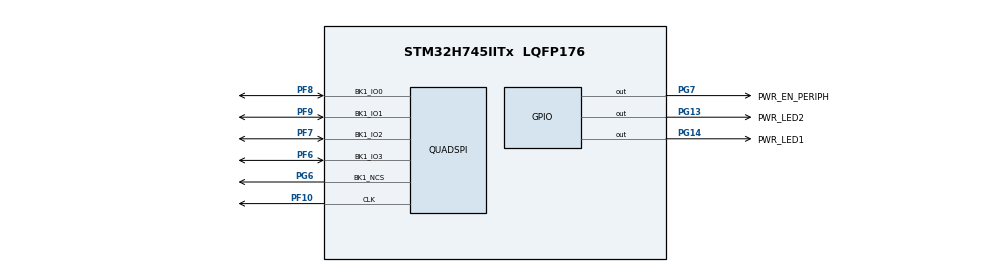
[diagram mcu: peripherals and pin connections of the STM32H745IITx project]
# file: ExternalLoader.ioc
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CortexM4.IPs=BDMA,CORTEX_M4\:I,DEBUG,DMA,FATFS_M4\:I,FREERTOS_M4\:I,IWDG2\:I,MDMA,NVIC2\:I,OPENAMP_M4\:I,PDM2PCM_M4\:I,PWR,RCC,RESMGR_UTILITY,SYS_M4\:I,USB_DEVICE_M4\:I,USB_HOST_M4\:I,VREFBUF,WWDG2\:I
CortexM7.IPs=BDMA\:I,CORTEX_M7\:I,DEBUG\:I,DMA\:I,FATFS_M7\:I,FREERTOS_M7\:I,IWDG1\:I,MDMA\:I,NVIC1\:I,OPENAMP_M7\:I,PDM2PCM_M7\:I,PWR\:I,RCC\:I,RESMGR_UTILITY\:I,SYS\:I,USB_DEVICE_M7\:I,USB_HOST_M7\:I,VREFBUF\:I,WWDG1\:I,QUADSPI\:I
CortexM7.Pins=PG7,PG13,PG14
Mcu.Family=STM32H7
Mcu.Name=STM32H745IITx
Mcu.Package=LQFP176
NVIC1.PriorityGroup=NVIC_PRIORITYGROUP_4
NVIC2.PriorityGroup=NVIC_PRIORITYGROUP_4
PA13\ (JTMS/SWDIO).Mode=Serial_Wire
PA13\ (JTMS/SWDIO).PinAttribute=CortexM7
PA13\ (JTMS/SWDIO).Signal=DEBUG_JTMS-SWDIO
PA14\ (JTCK/SWCLK).Mode=Serial_Wire
PA14\ (JTCK/SWCLK).PinAttribute=CortexM7
PA14\ (JTCK/SWCLK).Signal=DEBUG_JTCK-SWCLK
PF10.GPIO_Speed=GPIO_SPEED_FREQ_VERY_HIGH
PF10.Mode=Single Bank 1
PF10.PinAttribute=CortexM7
PF10.Signal=QUADSPI_CLK
PF6.GPIO_Speed=GPIO_SPEED_FREQ_VERY_HIGH
PF6.Mode=Single Bank 1
PF6.PinAttribute=CortexM7
PF6.Signal=QUADSPI_BK1_IO3
PF7.GPIO_Speed=GPIO_SPEED_FREQ_VERY_HIGH
PF7.Mode=Single Bank 1
PF7.PinAttribute=CortexM7
PF7.Signal=QUADSPI_BK1_IO2
PF8.GPIO_Speed=GPIO_SPEED_FREQ_VERY_HIGH
PF8.Mode=Single Bank 1
PF8.PinAttribute=CortexM7
PF8.Signal=QUADSPI_BK1_IO0
PF9.GPIO_Speed=GPIO_SPEED_FREQ_VERY_HIGH
PF9.Mode=Single Bank 1
PF9.PinAttribute=CortexM7
PF9.Signal=QUADSPI_BK1_IO1
PG13.GPIO_Label=PWR_LED2
PG13.PinAttribute=CortexM7
PG13.Signal=GPIO_Output
PG14.GPIO_Label=PWR_LED1
PG14.PinAttribute=CortexM7
PG14.Signal=GPIO_Output
PG6.GPIO_Speed=GPIO_SPEED_FREQ_VERY_HIGH
PG6.Mode=Single Bank 1
PG6.PinAttribute=CortexM7
PG6.Signal=QUADSPI_BK1_NCS
PG7.GPIO_Label=PWR_EN_PERIPH
PG7.PinAttribute=CortexM7
PG7.Signal=GPIO_Output
ProjectManager.HeapSize=0x200
ProjectManager.StackSize=0x400
ProjectManager.TargetToolchain=STM32CubeIDE
QUADSPI.ChipSelectHighTime=QSPI_CS_HIGH_TIME_3_CYCLE
QUADSPI.ClockPrescaler=5
QUADSPI.FlashSize=25
RCC.ADCFreq_Value=129000000
RCC.APB1Freq_Value=64000000
RCC.APB2Freq_Value=64000000
RCC.APB3Freq_Value=64000000
RCC.APB4Freq_Value=64000000
RCC.CortexFreq_Value=64000000
RCC.HCLKFreq_Value=64000000
RCC.SYSCLKFreq_VALUE=64000000
RCC.USBFreq_Value=129000000
SYS.userName=SYS_M7
VP_SYS_M4_VS_Systick.Mode=SysTick
board=custom

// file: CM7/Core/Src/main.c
/* USER CODE BEGIN Header */
/**
  ******************************************************************************
  * @file           : main.c
  * @brief          : Main program body
  ******************************************************************************
  * @attention
  *
  * <h2><center>&copy; Copyright (c) 2020 STMicroelectronics.
  * All rights reserved.</center></h2>
  *
  * This software component is licensed by ST under BSD 3-Clause license,
  * the "License"; You may not use this file except in compliance with the
  * License. You may obtain a copy of the License at:
  *                        opensource.org/licenses/BSD-3-Clause
  *
  ******************************************************************************
  */
/* USER CODE END Header */
#include "main.h"
#include "quadspi.h"
#include "gpio.h"

/* USER CODE BEGIN PD */

#ifndef HSEM_ID_0
#define HSEM_ID_0 (0U) /* HW semaphore 0*/
#endif
/* USER CODE END PD */

void SystemClock_Config(void);

int main(void)
{
/* USER CODE BEGIN Boot_Mode_Sequence_0 */
  int32_t timeout;
/* USER CODE END Boot_Mode_Sequence_0 */

/* USER CODE BEGIN Boot_Mode_Sequence_1 */
  /* Wait until CPU2 boots and enters in stop mode or timeout*/
  timeout = 0xFFFF;
  while((__HAL_RCC_GET_FLAG(RCC_FLAG_D2CKRDY) != RESET) && (timeout-- > 0));
  if ( timeout < 0 )
  {
  Error_Handler();
  }
/* USER CODE END Boot_Mode_Sequence_1 */
  /* MCU Configuration--------------------------------------------------------*/

  /* Reset of all peripherals, Initializes the Flash interface and the Systick. */
  HAL_Init();

  /* Configure the system clock */
  SystemClock_Config();
/* USER CODE BEGIN Boot_Mode_Sequence_2 */
/* When system initialization is finished, Cortex-M7 will release Cortex-M4 by means of
HSEM notification */
/*HW semaphore Clock enable*/
__HAL_RCC_HSEM_CLK_ENABLE();
/*Take HSEM */
HAL_HSEM_FastTake(HSEM_ID_0);
/*Release HSEM in order to notify the CPU2(CM4)*/
HAL_HSEM_Release(HSEM_ID_0,0);
/* wait until CPU2 wakes up from stop mode */
timeout = 0xFFFF;
while((__HAL_RCC_GET_FLAG(RCC_FLAG_D2CKRDY) == RESET) && (timeout-- > 0));
if ( timeout < 0 )
{
Error_Handler();
}
/* USER CODE END Boot_Mode_Sequence_2 */

  /* Initialize all configured peripherals */
  MX_GPIO_Init();
  MX_QUADSPI_Init();
  /* USER CODE BEGIN 2 */
  if (CSP_QUADSPI_Init() == HAL_OK)
  {

  }
  /* USER CODE END 2 */

  /* Infinite loop */
  while (1)
  {

  }
}

void SystemClock_Config(void)
{
  RCC_OscInitTypeDef RCC_OscInitStruct = {0};
  RCC_ClkInitTypeDef RCC_ClkInitStruct = {0};
  RCC_PeriphCLKInitTypeDef PeriphClkInitStruct = {0};

  /** Supply configuration update enable
  */
  HAL_PWREx_ConfigSupply(PWR_DIRECT_SMPS_SUPPLY);
  /** Configure the main internal regulator output voltage
  */
  __HAL_PWR_VOLTAGESCALING_CONFIG(PWR_REGULATOR_VOLTAGE_SCALE3);

  while(!__HAL_PWR_GET_FLAG(PWR_FLAG_VOSRDY)) {}
  /** Initializes the RCC Oscillators according to the specified parameters
  * in the RCC_OscInitTypeDef structure.
  */
  RCC_OscInitStruct.OscillatorType = RCC_OSCILLATORTYPE_HSI;
  RCC_OscInitStruct.HSIState = RCC_HSI_DIV1;
  RCC_OscInitStruct.HSICalibrationValue = RCC_HSICALIBRATION_DEFAULT;
  RCC_OscInitStruct.PLL.PLLState = RCC_PLL_NONE;
  if (HAL_RCC_OscConfig(&RCC_OscInitStruct) != HAL_OK)
  {
    Error_Handler();
  }
  /** Initializes the CPU, AHB and APB buses clocks
  */
  RCC_ClkInitStruct.ClockType = RCC_CLOCKTYPE_HCLK|RCC_CLOCKTYPE_SYSCLK
                              |RCC_CLOCKTYPE_PCLK1|RCC_CLOCKTYPE_PCLK2
                              |RCC_CLOCKTYPE_D3PCLK1|RCC_CLOCKTYPE_D1PCLK1;
  RCC_ClkInitStruct.SYSCLKSource = RCC_SYSCLKSOURCE_HSI;
  RCC_ClkInitStruct.SYSCLKDivider = RCC_SYSCLK_DIV1;
  RCC_ClkInitStruct.AHBCLKDivider = RCC_HCLK_DIV1;
  RCC_ClkInitStruct.APB3CLKDivider = RCC_APB3_DIV1;
  RCC_ClkInitStruct.APB1CLKDivider = RCC_APB1_DIV1;
  RCC_ClkInitStruct.APB2CLKDivider = RCC_APB2_DIV1;
  RCC_ClkInitStruct.APB4CLKDivider = RCC_APB4_DIV1;

  if (HAL_RCC_ClockConfig(&RCC_ClkInitStruct, FLASH_LATENCY_0) != HAL_OK)
  {
    Error_Handler();
  }
  PeriphClkInitStruct.PeriphClockSelection = RCC_PERIPHCLK_QSPI;
  PeriphClkInitStruct.QspiClockSelection = RCC_QSPICLKSOURCE_D1HCLK;
  if (HAL_RCCEx_PeriphCLKConfig(&PeriphClkInitStruct) != HAL_OK)
  {
    Error_Handler();
  }
}

void Error_Handler(void)
{
  __disable_irq();
  while (1)
  {
  }
}

/************************ (C) COPYRIGHT STMicroelectronics *****END OF FILE****/
